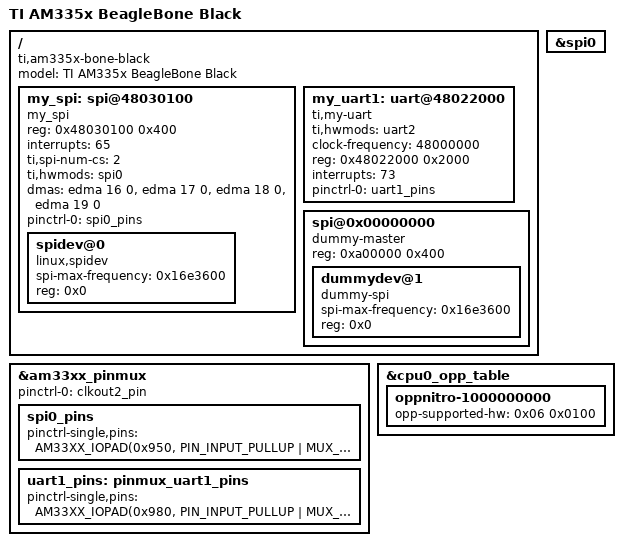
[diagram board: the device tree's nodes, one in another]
/*
 * Copyright (C) 2012 Texas Instruments Incorporated - http://www.ti.com/
 *
 * This program is free software; you can redistribute it and/or modify
 * it under the terms of the GNU General Public License version 2 as
 * published by the Free Software Foundation.
 */
/dts-v1/;

#include "am33xx.dtsi"
#include "am335x-bone-common.dtsi"
#include "am335x-boneblack-common.dtsi"

/ {
	model = "TI AM335x BeagleBone Black";
	compatible = "ti,am335x-bone-black", "ti,am335x-bone", "ti,am33xx";

    my_spi: spi@48030100 {
		compatible = "my_spi";
		#address-cells = <1>;
		#size-cells = <0>;
		reg = <0x48030100 0x400>;
		interrupts = <65>;
		ti,spi-num-cs = <2>;
		ti,hwmods = "spi0";
		dmas = <&edma 16 0
			&edma 17 0
			&edma 18 0
			&edma 19 0>;
		dma-names = "tx0", "rx0", "tx1", "rx1";
		status = "okay";

		pinctrl-names = "default";
		pinctrl-0 = <&spi0_pins>;
		spidev@0 {
			spi-max-frequency = <0x16e3600>;
			reg = <0x0>;
			compatible = "linux,spidev";
		};
	};

	my_uart1: uart@48022000 {
		compatible = "ti,my-uart";
		ti,hwmods = "uart2";
		clock-frequency = <48000000>;
		reg = <0x48022000 0x2000>;
		interrupts = <73>;
		status = "okay";
		pinctrl-names = "default";
		pinctrl-0 = <&uart1_pins>;
	};

	spi@0x00000000 {
		compatible = "dummy-master";
		#address-cells = <0x1>;
		#size-cells = <0x0>;
		reg = <0xa00000 0x400>;
		status = "okay";

		dummydev@1 {
			spi-max-frequency = <0x16e3600>;
			reg = <0x0>;
			compatible = "dummy-spi";
		};
	};
};

&am33xx_pinmux {
	pinctrl-names = "default";
	pinctrl-0 = <&clkout2_pin>;

	spi0_pins: spi0_pins {
		pinctrl-single,pins = <
			AM33XX_IOPAD(0x950, PIN_INPUT_PULLUP | MUX_MODE0)	/* spi0_sclk.spi0_sclk */
			AM33XX_IOPAD(0x954, PIN_INPUT_PULLUP | MUX_MODE0)	/* spi0_d0.spi0_d0 */
			AM33XX_IOPAD(0x958, PIN_OUTPUT_PULLUP | MUX_MODE0)	/* spi0_d1.spi0_d1 */
			AM33XX_IOPAD(0x95c, PIN_OUTPUT_PULLUP | MUX_MODE0)	/* spi0_cs0.spi0_cs0 */
		>;
	};
	uart1_pins: pinmux_uart1_pins {
		pinctrl-single,pins = <
			AM33XX_IOPAD(0x980, PIN_INPUT_PULLUP | MUX_MODE0)	/* uart0_rxd.uart0_rxd */
			AM33XX_IOPAD(0x984, PIN_OUTPUT_PULLDOWN | MUX_MODE0)	/* uart0_txd.uart0_txd */
		>;
	};
};

&spi0 {
		//status = "okay";
		pinctrl-names = "default";
		//pinctrl-0 = <&spi0_pins>;
		/*
		spidev@0 {
			spi-max-frequency = <0x16e3600>;
			reg = <0x0>;
			compatible = "linux,spidev";
		};
		*/
};


&cpu0_opp_table {
	/*
	 * All PG 2.0 silicon may not support 1GHz but some of the early
	 * BeagleBone Blacks have PG 2.0 silicon which is guaranteed
	 * to support 1GHz OPP so enable it for PG 2.0 on this board.
	 */
	oppnitro-1000000000 {
		opp-supported-hw = <0x06 0x0100>;
	};
};
